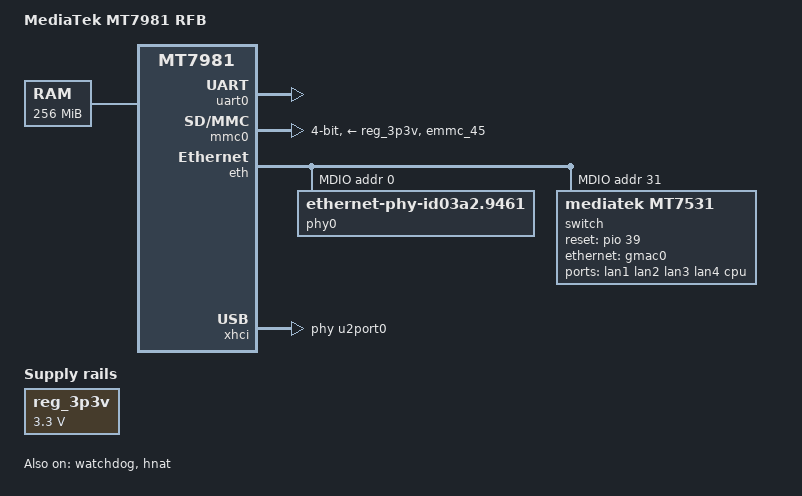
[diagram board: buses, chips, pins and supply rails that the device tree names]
/dts-v1/;
#include "mt7981.dtsi"
/ {
	model = "MediaTek MT7981 RFB";
	compatible = "mediatek,mt7981-sd-rfb";
	chosen {
		bootargs = "console=ttyS0,115200n1 loglevel=8  \
				earlycon=uart8250,mmio32,0x11002000 \
				root=PARTLABEL=rootfs rootfstype=squashfs,f2fs";
	};

	memory {
		// fpga ddr2: 128MB*2
		reg = <0 0x40000000 0 0x10000000>;
	};

	reg_3p3v: regulator-3p3v {
		compatible = "regulator-fixed";
		regulator-name = "fixed-3.3V";
		regulator-min-microvolt = <3300000>;
		regulator-max-microvolt = <3300000>;
		regulator-boot-on;
		regulator-always-on;
	};
};

&uart0 {
	status = "okay";
};

&watchdog {
	status = "okay";
};

&mmc0 {
         pinctrl-names = "default", "state_uhs";
         pinctrl-0 = <&mmc0_pins_default>;
         pinctrl-1 = <&mmc0_pins_uhs>;
         bus-width = <4>;
         max-frequency = <52000000>;
         cap-sd-highspeed;
         vmmc-supply = <&reg_3p3v>;
         vqmmc-supply = <&reg_3p3v>;
         status = "okay";
};

&eth {
	status = "okay";

	gmac0: mac@0 {
		compatible = "mediatek,eth-mac";
		reg = <0>;
		phy-mode = "2500base-x";

		fixed-link {
			speed = <2500>;
			full-duplex;
			pause;
		};
	};

	gmac1: mac@1 {
		compatible = "mediatek,eth-mac";
		reg = <1>;
		phy-mode = "gmii";
		phy-handle = <&phy0>;
	};

	mdio: mdio-bus {
		#address-cells = <1>;
		#size-cells = <0>;

		phy0: ethernet-phy@0 {
			compatible = "ethernet-phy-id03a2.9461";
			reg = <0>;
			phy-mode = "gmii";
			nvmem-cells = <&phy_calibration>;
			nvmem-cell-names = "phy-cal-data";
		};

		switch@0 {
			compatible = "mediatek,mt7531";
			reg = <31>;
			reset-gpios = <&pio 39 0>;

			ports {
				#address-cells = <1>;
				#size-cells = <0>;

				port@0 {
					reg = <0>;
					label = "lan1";
				};

				port@1 {
					reg = <1>;
					label = "lan2";
				};

				port@2 {
					reg = <2>;
					label = "lan3";
				};

				port@3 {
					reg = <3>;
					label = "lan4";
				};

				port@6 {
					reg = <6>;
					label = "cpu";
					ethernet = <&gmac0>;
					phy-mode = "2500base-x";

					fixed-link {
						speed = <2500>;
						full-duplex;
						pause;
					};
				};
			};
		};
	};
};

&hnat {
	mtketh-wan = "eth1";
	mtketh-lan = "lan";
	mtketh-max-gmac = <2>;
	status = "okay";
};

&spi1 {
	pinctrl-names = "default";
	pinctrl-0 = <&spic_pins>;
	status = "disabled";
};

&pio {

	spic_pins: spi1-pins {
		mux {
			function = "spi";
			groups = "spi1_1";
		};
	};

	mmc0_pins_default: mmc0-pins-default {
		mux {
			function = "flash";
			groups = "emmc_45";
		};
	};

	mmc0_pins_uhs: mmc0-pins-uhs {
		mux {
			function = "flash";
			groups = "emmc_45";
		};
	};
};

&xhci {
	mediatek,u3p-dis-msk = <0x0>;
	phys = <&u2port0 PHY_TYPE_USB2>,
	       <&u3port0 PHY_TYPE_USB3>;
	status = "okay";
};
